# N570F064_v4_2 register map
File version: 1.0
Registers are 32-bit, read-write, reset 0x0 unless marked. A register's access mark holds for its fields unless they carry their own. Offsets are from the block's base; [hi:lo] are bit positions; {n}, {i} and the like mark numbered series; 'fields as' and 'values as' point back to an identical list.

## ADC — ADC Register Map
Base 0x400E0000
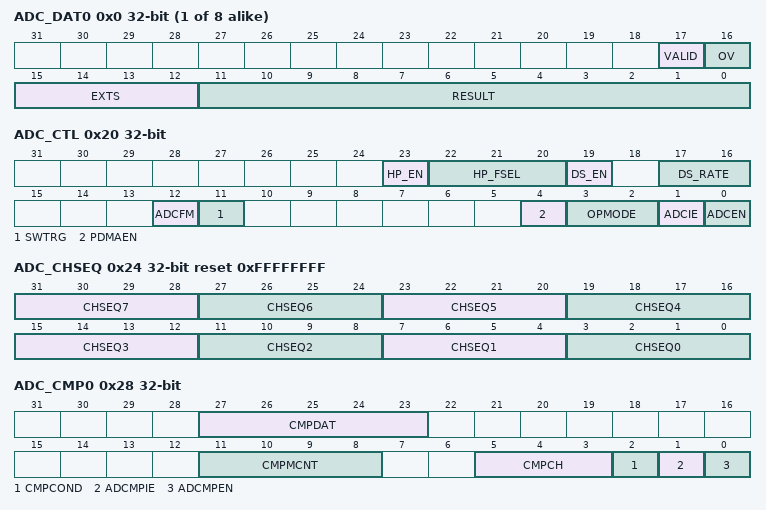
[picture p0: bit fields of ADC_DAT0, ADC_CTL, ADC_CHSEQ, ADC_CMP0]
{0x0+4i} ADC_DAT{i} ro (i=0..7) — A/D Data Register for the Channel Defined in CHSEQ{i}
  [17] VALID — Valid Flag. This bit is set to 1 when corresponding channel analog input conversion is completed and cleared by hardware after ADC_DAT register is read.
    0=Data in RESULT are not valid; 1=Data in RESULT are valid
  [16] OV — Over Run Flag. If converted data in RESULT[11:0] have not been read before new conversion result is loaded to this register, OV is set to 1. It is cleared by hardware after ADC_DAT register is read.
    0=Data in RESULT are recent conversion result; 1=Data in RESULT are overwritten
  [15:12] EXTS — Extension Bits Of RESULT for Different Data Format. If ADCFM is "0", EXTS all are read as "0". If ADCFM is "1", EXTS all are read as bit RESULT[11].
  [11:0] RESULT — A/D Conversion Result. This field contains the 12-bit conversion result. Its data format is defined by ADCFM bit.
0x20 ADC_CTL — A/D Control Register
  [23] HP_EN — High-pass Filter Enable
    0=High-pass filter is disabled; 1=High-pass filter is enabled (must in continuous scan mode)
  [22:20] HP_FSEL — High-pass Filter Frequency Selection:
    0=Do not remove DC part; 1=DC part is suppressed by -40dB, -3dB at 0.005 x Sampling Rate; 2=DC part is suppressed by -40dB, -3dB at 0.010 x Sampling Rate; 3=DC part is suppressed by -40dB, -3dB at 0.014 x Sampling Rate; 4=DC part is suppressed by -40dB, -3dB at 0.019 x Sampling Rate; 5=DC part is suppressed by -40dB, -3dB at 0.023 x Sampling Rate; 6=DC part is suppressed by -40dB, -3dB at 0.027 x Sampling Rate; 7=DC part is suppressed by -40dB, -3dB at 0.032 x Sampling Rate
  [19] DS_EN — Down Sample Function Enable
    0=Down sample function is disabled; 1=Down sample function is enabled. When this field is set, ADC will be forced to continuous scan mode, no matter what is specified in field OPMODE (ADC_CTL[3:2])
  [17:16] DS_RATE — Down Sample Rate
    0=Down sample X2; 1=Down sample X4; 2=Down sample X8; 3=Down sample X16
  [12] ADCFM — Data Format Of ADC Conversion Result
    0=Unsigned; 1=2'Complemet
  [11] SWTRG — A/D Conversion Start. Note: SWTRG bit can be reset to 0 by software, or can be cleared to 0 by hardware automatically at the end of single mode and single-cycle scan mode on specified channel. In continuous scan mode, A/D conversion is continuously performed sequentially until software writes 0 to this bit or chip resets.
    0=Conversion is stopped and A/D converter enters idle state; 1=Start conversion
  [4] PDMAEN — PDMA Transfer Enable Bit . When A/D conversion is completed, the converted data is loaded into ADC_DATn (n: 0 ~ 7) register, user can enable this bit to generate a PDMA data transfer request.
    0=PDMA data transfer Disabled; 1=PDMA data transfer Enabled
  [3:2] OPMODE — A/D Converter Operation Mode . Note 1: This field will be effective only when DS_EN field in this register is set as "0". When DS_EN is set as "1", ADC conversion will be forced to "continuous scan mode" Note 2: When changing the operation mode, software should disable SWTRG bit firstly.
    0=Single conversion; 2=Single-cycle scan; 3=Continuous scan
  [1] ADCIE — A/D Interrupt Enable. A/D conversion end interrupt request is generated if ADCIE bit is set to 1.
    0=Disable A/D interrupt function; 1=Enable A/D interrupt function
  [0] ADCEN — A/D Converter Enable. Before starting A/D conversion function, this bit should be set to 1. Clear it to 0 to disable A/D converter analog circuit power consumption.
    0=Disable; 1=Enable
0x24 ADC_CHSEQ reset 0xFFFFFFFF — A/D Channel Sequence Register
  [4n+3:4n] CHSEQ{n} (n=3..7) — Select Channel N As The {n+1}th Conversion In Scan Sequence. The definition of channel selection is the same as CHSEQ0.
  [11:8] CHSEQ2 — Select Channel N As The 3rd Conversion In Scan Sequence. The definition of channel selection is the same as CHSEQ0.
  [7:4] CHSEQ1 — Select Channel N As The 2nd Conversion In Scan Sequence. The definition of channel selection is the same as CHSEQ0.
  [3:0] CHSEQ0 — Select Channel N As The 1st Conversion In Scan Sequence
0x28 ADC_CMP0 — A/D Compare Register 0
  [27:23] CMPDAT — Compare Data. This field possessing the 5 MSB of 12-bit compare data, and 7 LSB are treated as "0", is used to compare with conversion result of specified channel. Software can use it to monitor the external analog input pin voltage transition in scan mode without imposing a load on software. The data format should be consistent with the setting of ADCFM bit.
  [11:8] CMPMCNT — Compare Match Count. When the specified A/D channel analog conversion result matches the comparing condition, the internal match counter will increase 1. When the internal counter achieves the setting, (CMPMCNT+1) hardware will set the ADCMPF bit.
  [5:3] CMPCH — Compare Channel Selection
    {v}=Channel {v} conversion result is selected to be compared (v=0..3); 5=The conversion result of pre-amplifier output is selected to be compared; 6=Channel 6 conversion result is selected to be compared; 7=Channel 7 conversion result is selected to be compared
  [2] CMPCOND — Compare Condition
    0=ADCMPFx bit is set if conversion result is less than CMPDAT; 1=ADCMPFx bit is set if conversion result is greater or equal to CMPDAT,
  [1] ADCMPIE — Compare Interrupt Enable. When converted data in RESULT is less (or greater) than the compare data CMPDAT, ADCMPF bit is asserted. If ADCMPIE is set to 1, a compare interrupt request is generated.
    0=Disable; 1=Enable
  [0] ADCMPEN — Compare Enable. Set this bit to 1 to enable the comparison CMPDAT with specified channel conversion result when converted data is loaded into ADC_DAT register.
    0=Disable compare; 1=Enable compare
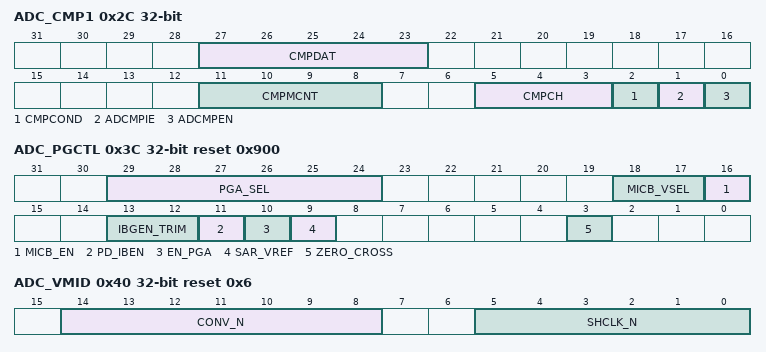
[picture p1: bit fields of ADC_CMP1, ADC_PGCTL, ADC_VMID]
0x2C ADC_CMP1 — A/D Compare Register 1
  fields as ADC_CMP0
0x30 ADC_STATUS reset 0x70 — A/D Status Register
  [15:0] PDMA_RESULT — ADC PDMA transfer data . If DW_EN is "0" and HPF_EN is "0", transfer SAR output to SRAM. If DW_EN is "1" and HPF_EN is "0", transfer DW output to SRAM. If HPF_EN is "1", transfer HPF output to SRAM
0x34 ADC_PDMA — ADC PDMA Control Register
0x3C ADC_PGCTL reset 0x900 — ADC Pre-amplifier Gain Control Register
  [29:24] PGA_SEL
  [18:17] MICB_VSEL — Select MIC BIAS level. 0: 0%,1:65%,2:70%,3:50% of VCCA
  [16] MICB_EN — 1: Enable MIC_BIAS
  [13:12] IBGEN_TRIM — Set to 0
  [11] PD_IBEN — 1: Power down analog bias generation
  [10] EN_PGA — 1: Enable PGA 0: Disable PGA
  [9] SAR_VREF
  [3] ZERO_CROSS — 1: Gain update only on zero crossing. 0: immediate
0x40 ADC_VMID reset 0x6 — ADC VMID Control Register
  [14:8] CONV_N — Specify ADC conversion clock number. CONV_N has to be equal to or great than 11. To update this field, programmer can only revise bit [14:8] and keep other bits the same as before. Note: CONV_N valid range is from 11~127
  [5:0] SHCLK_N — Specify the high level of ADC start signal. Note: Suggested and default value is 0.
0x44 ADC_HWPARA reset 0xB00 — ADC H/W Parameter Control Register
